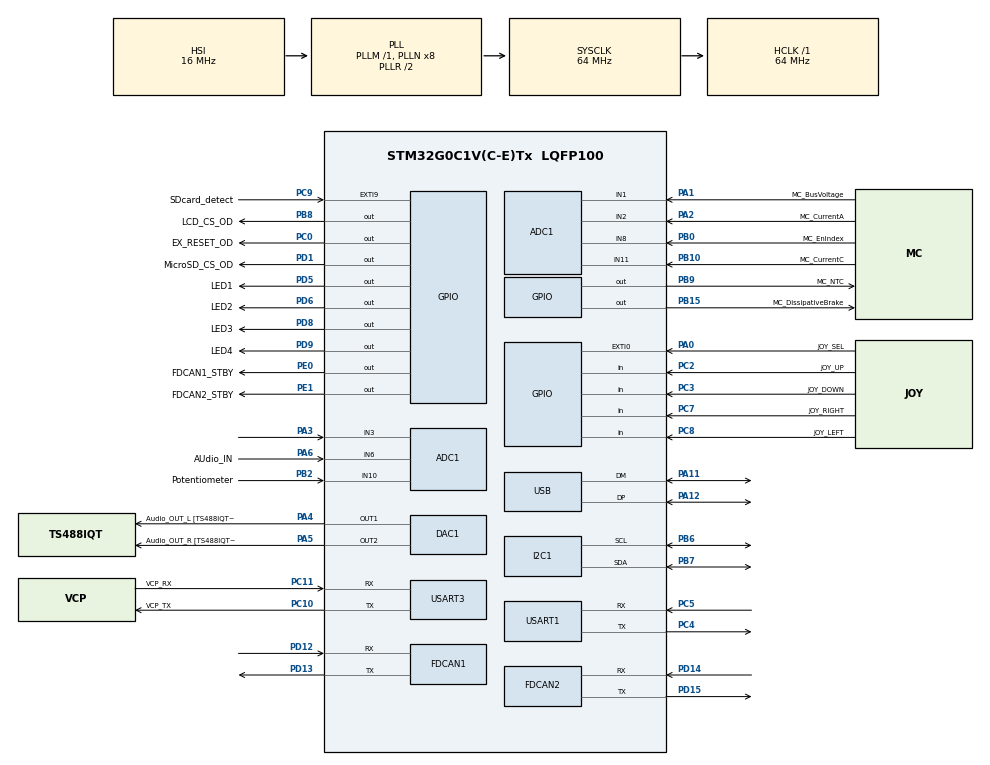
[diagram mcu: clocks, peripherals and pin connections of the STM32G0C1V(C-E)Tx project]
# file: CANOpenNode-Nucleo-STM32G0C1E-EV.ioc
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ADC1.Channel-0\#ChannelRegularConversion=ADC_CHANNEL_1
ADC1.NbrOfConversionFlag=1
ADC1.Rank-0\#ChannelRegularConversion=1
ADC1.SamplingTime-0\#ChannelRegularConversion=ADC_SAMPLINGTIME_COMMON_1
ADC1.SelectedChannel=ADC_CHANNEL_1|ADC_CHANNEL_2|ADC_CHANNEL_3|ADC_CHANNEL_6|ADC_CHANNEL_8|ADC_CHANNEL_10|ADC_CHANNEL_11
ADC1.master=1
DAC1.DAC_Channel-DAC_OUT1=DAC_CHANNEL_1
DAC1.DAC_Channel-DAC_OUT2=DAC_CHANNEL_2
FDCAN1.AutoRetransmission=ENABLE
FDCAN1.ClockDivider=FDCAN_CLOCK_DIV1
FDCAN1.DataPrescaler=16
FDCAN1.DataTimeSeg1=13
FDCAN1.DataTimeSeg2=2
FDCAN1.NominalPrescaler=32
FDCAN1.NominalTimeSeg1=13
FDCAN1.NominalTimeSeg2=2
I2C1.Timing=0x10707DBC
Mcu.Family=STM32G0
Mcu.Name=STM32G0C1V(C-E)Tx
Mcu.Package=LQFP100
NVIC.TIM16_FDCAN_IT0_IRQn=true\:0\:0\:false\:false\:true\:true\:true\:true
NVIC.TIM17_FDCAN_IT1_IRQn=true\:0\:0\:false\:false\:true\:true\:true\:true
PA0.GPIO_Label=JOY_SEL
PA0.Signal=GPXTI0
PA1.GPIO_Label=MC_BusVoltage
PA1.Mode=IN1
PA1.Signal=ADC1_IN1
PA10.GPIO_Label=MC_WH
PA10.Signal=S_TIM1_CH3
PA11\ [PA9].Mode=Device
PA11\ [PA9].Signal=USB_DM
PA12\ [PA10].Mode=Device
PA12\ [PA10].Signal=USB_DP
PA13.Mode=Serial_Wire
PA13.Signal=SYS_SWDIO
PA14-BOOT0.Mode=Serial_Wire
PA14-BOOT0.Signal=SYS_SWCLK
PA2.GPIO_Label=MC_CurrentA
PA2.Mode=IN2
PA2.Signal=ADC1_IN2
PA3.Mode=IN3
PA3.Signal=ADC1_IN3
PA4.GPIO_Label=Audio_OUT_L [TS488IQT_VIN1]
PA4.Signal=COMP_DAC11_group
PA5.GPIO_Label=Audio_OUT_R [TS488IQT_VIN2]
PA5.Signal=COMP_DAC12_group
PA6.GPIO_Label=AUdio_IN
PA6.Mode=IN6
PA6.Signal=ADC1_IN6
PA7.Signal=SPI1_MOSI
PA8.GPIO_Label=MC_UH
PA8.Signal=S_TIM1_CH1
PA9.GPIO_Label=MC_VH
PA9.Signal=S_TIM1_CH2
PB0.GPIO_Label=MC_EnIndex
PB0.Mode=IN8
PB0.Signal=ADC1_IN8
PB1.GPIO_Label=MC_PFCpwm
PB1.Signal=S_TIM3_CH4
PB10.GPIO_Label=MC_CurrentC
PB10.Mode=IN11
PB10.Signal=ADC1_IN11
PB12.GPIO_Label=MC_EmergencySTOP
PB12.Signal=TIM1_BK
PB15.GPIO_Label=MC_DissipativeBrake
PB15.Signal=GPIO_Output
PB2.GPIO_Label=Potentiometer
PB2.Mode=IN10
PB2.Signal=ADC1_IN10
PB3.Signal=SPI1_SCK
PB5.GPIO_Label=MC_EnB
PB5.Signal=S_TIM3_CH2
PB6.GPIO_Pu=GPIO_PULLUP
PB6.Mode=I2C
PB6.Signal=I2C1_SCL
PB7.GPIO_Pu=GPIO_PULLUP
PB7.Mode=I2C
PB7.Signal=I2C1_SDA
PB8.GPIO_Label=LCD_CS_OD
PB8.GPIO_ModeDefaultOutputPP=GPIO_MODE_OUTPUT_OD
PB8.Signal=GPIO_Output
PB9.GPIO_Label=MC_NTC
PB9.Signal=GPIO_Output
PC0.GPIO_Label=EX_RESET_OD
PC0.GPIO_ModeDefaultOutputPP=GPIO_MODE_OUTPUT_OD
PC0.Signal=GPIO_Output
PC1.GPIO_Label=MC_PFCsync1
PC1.Signal=LPTIM1_OUT
PC10.GPIO_Label=VCP_TX
PC10.Mode=Asynchronous
PC10.Signal=USART3_TX
PC11.GPIO_Label=VCP_RX
PC11.Mode=Asynchronous
PC11.Signal=USART3_RX
PC13.GPIO_Label=Tamper_key
PC13.Signal=RTC_TAMP_IN1
PC14-OSC32_IN\ (PC14).Mode=LSE-External-Oscillator
PC14-OSC32_IN\ (PC14).Signal=RCC_OSC32_IN
PC15-OSC32_OUT\ (PC15).Mode=LSE-External-Oscillator
PC15-OSC32_OUT\ (PC15).Signal=RCC_OSC32_OUT
PC2.GPIO_Label=JOY_UP
PC2.Signal=GPIO_Input
PC3.GPIO_Label=JOY_DOWN
PC3.Signal=GPIO_Input
PC4.Mode=Asynchronous
PC4.Signal=USART1_TX
PC5.Mode=Asynchronous
PC5.Signal=USART1_RX
PC6.GPIO_Label=MC_EnA
PC6.Signal=S_TIM3_CH1
PC7.GPIO_Label=JOY_RIGHT
PC7.Signal=GPIO_Input
PC8.GPIO_Label=JOY_LEFT
PC8.Signal=GPIO_Input
PC9.GPIO_Label=SDcard_detect
PC9.Signal=GPXTI9
PD0.GPIO_Label=MC_PFCsync2
PD0.Signal=S_TIM16_CH1
PD1.GPIO_Label=MicroSD_CS_OD
PD1.GPIO_ModeDefaultOutputPP=GPIO_MODE_OUTPUT_OD
PD1.Signal=GPIO_Output
PD12.Mode=FDCAN_Activate
PD12.Signal=FDCAN1_RX
PD13.Mode=FDCAN_Activate
PD13.Signal=FDCAN1_TX
PD14.Mode=FDCAN_Activate
PD14.Signal=FDCAN2_RX
PD15.Mode=FDCAN_Activate
PD15.Signal=FDCAN2_TX
PD2.GPIO_Label=MC_UL
PD2.Signal=TIM1_CH1N
PD3.GPIO_Label=MC_VL
PD3.Signal=TIM1_CH2N
PD4.GPIO_Label=MC_WL
PD4.Signal=TIM1_CH3N
PD5.GPIO_Label=LED1
PD5.Signal=GPIO_Output
PD6.GPIO_Label=LED2
PD6.Signal=GPIO_Output
PD8.GPIO_Label=LED3
PD8.Signal=GPIO_Output
PD9.GPIO_Label=LED4
PD9.Signal=GPIO_Output
PE0.GPIO_Label=FDCAN1_STBY
PE0.Signal=GPIO_Output
PE1.GPIO_Label=FDCAN2_STBY
PE1.Signal=GPIO_Output
PF0-OSC_IN\ (PF0).Mode=HSE-External-Oscillator
PF0-OSC_IN\ (PF0).Signal=RCC_OSC_IN
PF1-OSC_OUT\ (PF1).Mode=HSE-External-Oscillator
PF1-OSC_OUT\ (PF1).Signal=RCC_OSC_OUT
ProjectManager.HeapSize=0x200
ProjectManager.StackSize=0x400
ProjectManager.TargetToolchain=STM32CubeIDE
RCC.ADCFreq_Value=64000000
RCC.AHBFreq_Value=64000000
RCC.CortexFreq_Value=64000000
RCC.EXTERNAL_CLOCK_VALUE=48000
RCC.HCLKFreq_Value=64000000
RCC.HSE_VALUE=8000000
RCC.HSI48_VALUE=48000000
RCC.HSI_VALUE=16000000
RCC.SYSCLKFreq_VALUE=64000000
RCC.SYSCLKSource=RCC_SYSCLKSOURCE_PLLCLK
RCC.USBFreq_Value=48000000
RCC.VCOOutputFreq_Value=128000000
SH.COMP_DAC11_group.0=DAC1_OUT1,DAC_OUT1
SH.COMP_DAC12_group.0=DAC1_OUT2,DAC_OUT2
SH.S_TIM16_CH1.0=TIM16_CH1
SH.S_TIM1_CH1.0=TIM1_CH1
SH.S_TIM1_CH2.0=TIM1_CH2
SH.S_TIM1_CH3.0=TIM1_CH3
SH.S_TIM3_CH1.0=TIM3_CH1
SH.S_TIM3_CH2.0=TIM3_CH2
SH.S_TIM3_CH4.0=TIM3_CH4
TIM17.Period=999
TIM17.Prescaler=63
USART1.VirtualMode-Asynchronous=VM_ASYNC
USART3.VirtualMode-Asynchronous=VM_ASYNC
USART3.WordLength=WORDLENGTH_7B
VP_SYS_VS_DBSignals.Mode=DisableDeadBatterySignals
VP_TIM17_VS_ClockSourceINT.Mode=Enable_Timer
board=STM32G0C1E-EV

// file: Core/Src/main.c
/* USER CODE BEGIN Header */
/**
  ******************************************************************************
  * @file           : main.c
  * @brief          : Main program body
  ******************************************************************************
  * @attention
  *
  * Copyright (c) 2022 STMicroelectronics.
  * All rights reserved.
  *
  * This software is licensed under terms that can be found in the LICENSE file
  * in the root directory of this software component.
  * If no LICENSE file comes with this software, it is provided AS-IS.
  *
  ******************************************************************************
  */
/* USER CODE END Header */
#include "main.h"
#include "adc.h"
#include "dac.h"
#include "fdcan.h"
#include "i2c.h"
#include "tim.h"
#include "usart.h"
#include "usb_drd_fs.h"
#include "gpio.h"

/* USER CODE BEGIN Includes */
#include "CO_app_STM32.h"
/* USER CODE END Includes */

void SystemClock_Config(void);

int main(void)
{

  /* MCU Configuration--------------------------------------------------------*/

  /* Reset of all peripherals, Initializes the Flash interface and the Systick. */
  HAL_Init();

  /* Configure the system clock */
  SystemClock_Config();

  /* Initialize all configured peripherals */
  MX_GPIO_Init();
  MX_ADC1_Init();
  MX_DAC1_Init();
  MX_FDCAN1_Init();
  MX_FDCAN2_Init();
  MX_I2C1_Init();
  MX_USART1_UART_Init();
  MX_USART3_UART_Init();
  MX_USB_DRD_FS_PCD_Init();
  MX_TIM17_Init();
  /* USER CODE BEGIN 2 */

  CANopenNodeSTM32 CANOpenConfig;
  CANOpenConfig.CANHandle = &hfdcan1;
  CANOpenConfig.HWInitFunction = MX_FDCAN1_Init;
  CANOpenConfig.timerHandle = &htim17;
  CANOpenConfig.desiredNodeID = 21;
  CANOpenConfig.baudrate = 125;
  canopen_app_init(&CANOpenConfig);
  /* USER CODE END 2 */

  /* Infinite loop */
  /* USER CODE BEGIN WHILE */
  while (1)
  {
	  canopen_app_process();
    /* USER CODE END WHILE */

  }
}

void SystemClock_Config(void)
{
  RCC_OscInitTypeDef RCC_OscInitStruct = {0};
  RCC_ClkInitTypeDef RCC_ClkInitStruct = {0};

  /** Configure the main internal regulator output voltage
  */
  HAL_PWREx_ControlVoltageScaling(PWR_REGULATOR_VOLTAGE_SCALE1);

  /** Initializes the RCC Oscillators according to the specified parameters
  * in the RCC_OscInitTypeDef structure.
  */
  RCC_OscInitStruct.OscillatorType = RCC_OSCILLATORTYPE_HSI|RCC_OSCILLATORTYPE_HSI48;
  RCC_OscInitStruct.HSIState = RCC_HSI_ON;
  RCC_OscInitStruct.HSI48State = RCC_HSI48_ON;
  RCC_OscInitStruct.HSIDiv = RCC_HSI_DIV1;
  RCC_OscInitStruct.HSICalibrationValue = RCC_HSICALIBRATION_DEFAULT;
  RCC_OscInitStruct.PLL.PLLState = RCC_PLL_ON;
  RCC_OscInitStruct.PLL.PLLSource = RCC_PLLSOURCE_HSI;
  RCC_OscInitStruct.PLL.PLLM = RCC_PLLM_DIV1;
  RCC_OscInitStruct.PLL.PLLN = 8;
  RCC_OscInitStruct.PLL.PLLP = RCC_PLLP_DIV2;
  RCC_OscInitStruct.PLL.PLLQ = RCC_PLLQ_DIV2;
  RCC_OscInitStruct.PLL.PLLR = RCC_PLLR_DIV2;
  if (HAL_RCC_OscConfig(&RCC_OscInitStruct) != HAL_OK)
  {
    Error_Handler();
  }

  /** Initializes the CPU, AHB and APB buses clocks
  */
  RCC_ClkInitStruct.ClockType = RCC_CLOCKTYPE_HCLK|RCC_CLOCKTYPE_SYSCLK
                              |RCC_CLOCKTYPE_PCLK1;
  RCC_ClkInitStruct.SYSCLKSource = RCC_SYSCLKSOURCE_PLLCLK;
  RCC_ClkInitStruct.AHBCLKDivider = RCC_SYSCLK_DIV1;
  RCC_ClkInitStruct.APB1CLKDivider = RCC_HCLK_DIV1;

  if (HAL_RCC_ClockConfig(&RCC_ClkInitStruct, FLASH_LATENCY_2) != HAL_OK)
  {
    Error_Handler();
  }
}

void Error_Handler(void)
{
  __disable_irq();
  while (1)
  {
  }
}
